# R9A09G057H register map
Vendor: Renesas Electronics; File version: 1.00
CPU: other r0p3, little endian, MPU, FPU, vendor SysTick, 4 interrupt priority bits, 480 interrupts
Registers are 32-bit, read-write, no defined reset value unless marked. A register's access mark holds for its fields unless they carry their own. Offsets are from the block's base; [hi:lo] are bit positions; lines under a group give offsets from that group; {n}, {i} and the like mark numbered series; 'fields as' and 'values as' point back to an identical list.

## R_GBETH0 — IO define file for tzc.
Base 0x15C30000
Same registers: R_GBETH1 0x15C40000
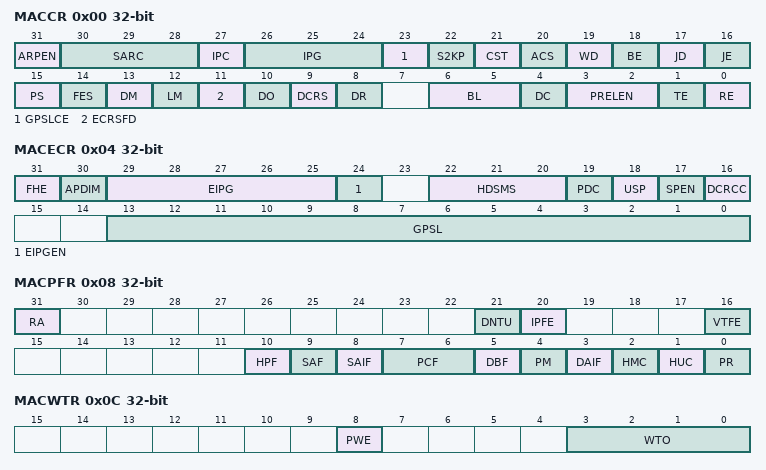
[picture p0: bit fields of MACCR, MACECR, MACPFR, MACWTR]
0x00 MACCR
  [31] ARPEN, [30:28] SARC, [27] IPC, [26:24] IPG, [23] GPSLCE, [22] S2KP, [21] CST, [20] ACS, [19] WD, [18] BE, [17] JD, [16] JE, [15] PS, [14] FES, [13] DM, [12] LM, [11] ECRSFD, [10] DO, [9] DCRS, [8] DR, [6:5] BL, [4] DC, [3:2] PRELEN, [1] TE, [0] RE
0x04 MACECR
  [31] FHE, [30] APDIM, [29:25] EIPG, [24] EIPGEN, [22:20] HDSMS, [19] PDC, [18] USP, [17] SPEN, [16] DCRCC, [13:0] GPSL
0x08 MACPFR
  [31] RA, [21] DNTU, [20] IPFE, [16] VTFE, [10] HPF, [9] SAF, [8] SAIF, [7:6] PCF, [5] DBF, [4] PM, [3] DAIF, [2] HMC, [1] HUC, [0] PR
0x0C MACWTR
  [8] PWE, [3:0] WTO
{0x10+4i} MACHTR{i} (i=0..7)
  [31:0] HT{32i+31}T{32i}
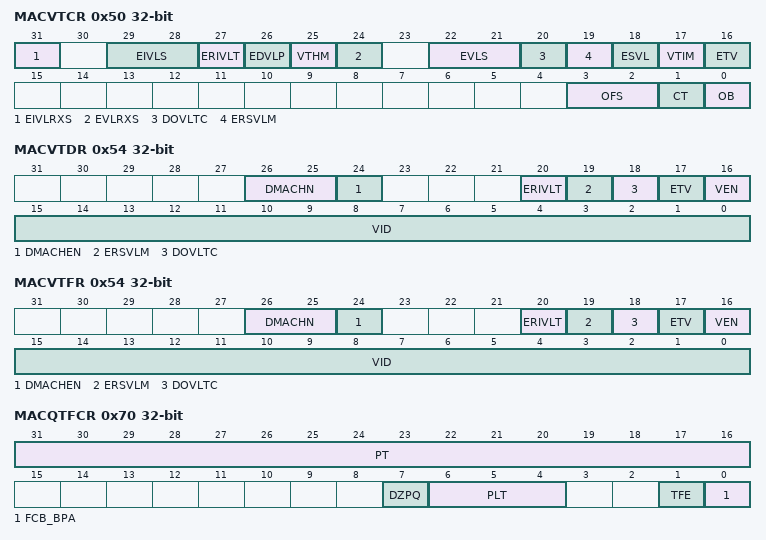
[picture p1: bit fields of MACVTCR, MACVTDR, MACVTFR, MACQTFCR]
0x50 MACVTCR
  [31] EIVLRXS, [29:28] EIVLS, [27] ERIVLT, [26] EDVLP, [25] VTHM, [24] EVLRXS, [22:21] EVLS, [20] DOVLTC, [19] ERSVLM, [18] ESVL, [17] VTIM, [16] ETV, [3:2] OFS, [1] CT, [0] OB
0x54 MACVTDR
  [26:25] DMACHN, [24] DMACHEN, [20] ERIVLT, [19] ERSVLM, [18] DOVLTC, [17] ETV, [16] VEN, [15:0] VID
0x54 MACVTFR
  fields as MACVTDR
0x58 MACVHTR
  [15:0] VLHT
0x70 MACQTFCR
  [31:16] PT, [7] DZPQ, [6:4] PLT, [1] TFE, [0] FCB_BPA
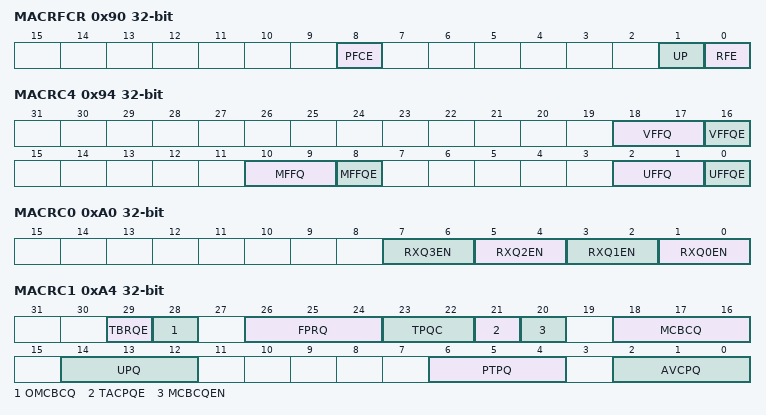
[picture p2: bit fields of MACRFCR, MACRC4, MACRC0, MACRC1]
0x90 MACRFCR
  [8] PFCE, [1] UP, [0] RFE
0x94 MACRC4
  [18:17] VFFQ, [16] VFFQE, [10:9] MFFQ, [8] MFFQE, [2:1] UFFQ, [0] UFFQE
0xA0 MACRC0
  [2n+1:2n] RXQ{n}EN (n=0..3)
0xA4 MACRC1
  [29] TBRQE, [28] OMCBCQ, [26:24] FPRQ, [23:22] TPQC, [21] TACPQE, [20] MCBCQEN, [18:16] MCBCQ, [14:12] UPQ, [6:4] PTPQ, [2:0] AVCPQ
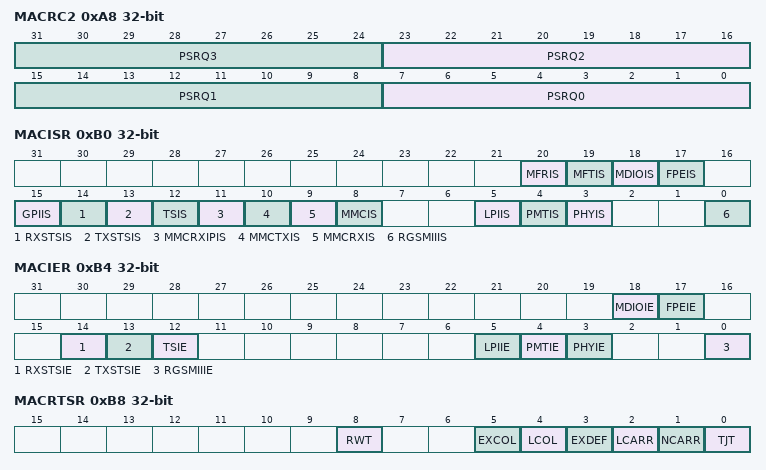
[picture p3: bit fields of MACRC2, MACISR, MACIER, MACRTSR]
0xA8 MACRC2
  [8n+7:8n] PSRQ{n} (n=0..3)
0xB0 MACISR ro
  [20] MFRIS, [19] MFTIS, [18] MDIOIS, [17] FPEIS, [15] GPIIS, [14] RXSTSIS, [13] TXSTSIS, [12] TSIS, [11] MMCRXIPIS, [10] MMCTXIS, [9] MMCRXIS, [8] MMCIS, [5] LPIIS, [4] PMTIS, [3] PHYIS, [0] RGSMIIIS
0xB4 MACIER
  [18] MDIOIE, [17] FPEIE, [14] RXSTSIE, [13] TXSTSIE, [12] TSIE, [5] LPIIE, [4] PMTIE, [3] PHYIE, [0] RGSMIIIE
0xB8 MACRTSR
  [8] RWT, [5] EXCOL, [4] LCOL, [3] EXDEF, [2] LCARR, [1] NCARR, [0] TJT
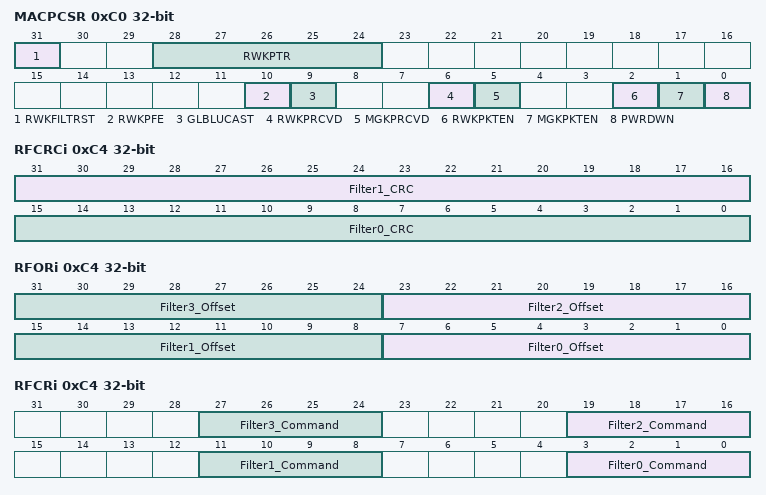
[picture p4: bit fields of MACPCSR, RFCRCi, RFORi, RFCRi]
0xC0 MACPCSR
  [31] RWKFILTRST, [28:24] RWKPTR ro, [10] RWKPFE, [9] GLBLUCAST, [6] RWKPRCVD, [5] MGKPRCVD, [2] RWKPKTEN, [1] MGKPKTEN, [0] PWRDWN
0xC4 RFBMRi
  [31:0] Filter0_Byte_Mask
0xC4 RFCRCi
  [31:16] Filter1_CRC, [15:0] Filter0_CRC
0xC4 RFORi
  [8n+7:8n] Filter{n}_Offset (n=0..3)
0xC4 RFCRi
  [8n+3:8n] Filter{n}_Command (n=0..3)
0xC4 MACRPFR
  [31:0] WKUPFRMFTR
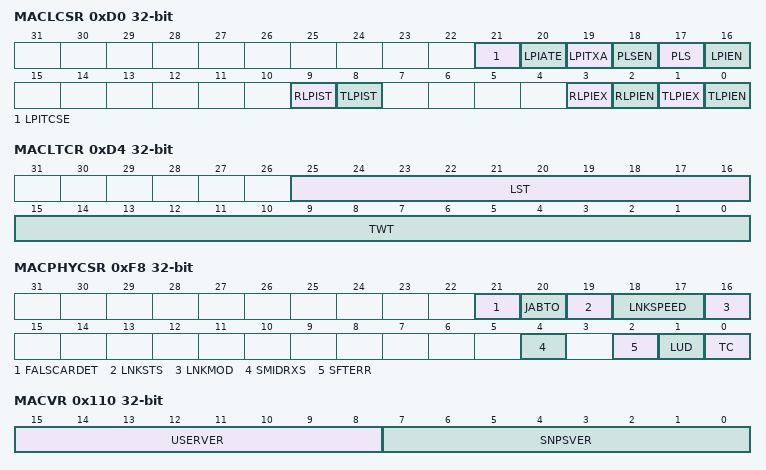
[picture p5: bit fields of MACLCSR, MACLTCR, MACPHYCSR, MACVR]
0xD0 MACLCSR
  [21] LPITCSE, [20] LPIATE, [19] LPITXA, [18] PLSEN, [17] PLS, [16] LPIEN, [9] RLPIST, [8] TLPIST, [3] RLPIEX, [2] RLPIEN, [1] TLPIEX, [0] TLPIEN
0xD4 MACLTCR
  [25:16] LST, [15:0] TWT
0xD8 MACLETR
  [19:3] LPIET
0xDC MAC1TCR
  [11:0] TIC_1US_CNTR
0xF8 MACPHYCSR
  [21] FALSCARDET ro, [20] JABTO ro, [19] LNKSTS ro, [18:17] LNKSPEED ro, [16] LNKMOD ro, [4] SMIDRXS, [2] SFTERR, [1] LUD, [0] TC
0x110 MACVR ro
  [15:8] USERVER, [7:0] SNPSVER
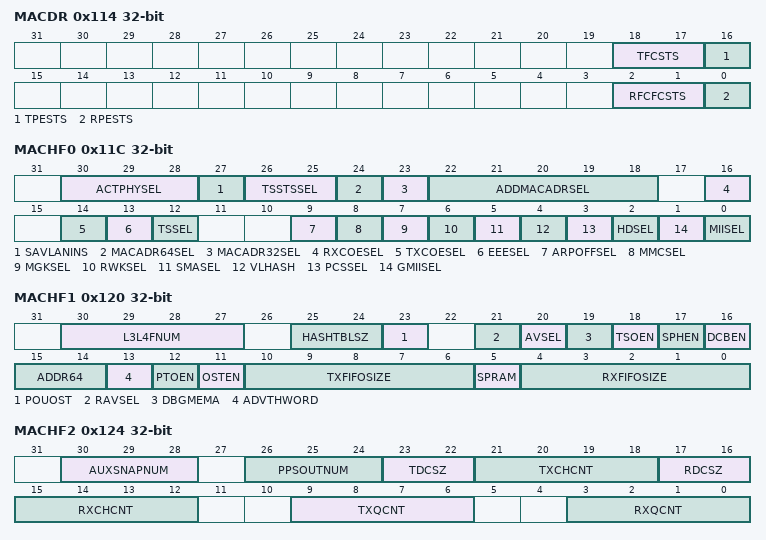
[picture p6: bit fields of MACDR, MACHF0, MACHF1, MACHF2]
0x114 MACDR ro
  [18:17] TFCSTS, [16] TPESTS, [2:1] RFCFCSTS, [0] RPESTS
0x11C MACHF0 ro
  [30:28] ACTPHYSEL, [27] SAVLANINS, [26:25] TSSTSSEL, [24] MACADR64SEL, [23] MACADR32SEL, [22:18] ADDMACADRSEL, [16] RXCOESEL, [14] TXCOESEL, [13] EEESEL, [12] TSSEL, [9] ARPOFFSEL, [8] MMCSEL, [7] MGKSEL, [6] RWKSEL, [5] SMASEL, [4] VLHASH, [3] PCSSEL, [2] HDSEL, [1] GMIISEL, [0] MIISEL
0x120 MACHF1 ro
  [30:27] L3L4FNUM, [25:24] HASHTBLSZ, [23] POUOST, [21] RAVSEL, [20] AVSEL, [19] DBGMEMA, [18] TSOEN, [17] SPHEN, [16] DCBEN, [15:14] ADDR64, [13] ADVTHWORD, [12] PTOEN, [11] OSTEN, [10:6] TXFIFOSIZE, [5] SPRAM, [4:0] RXFIFOSIZE
0x124 MACHF2 ro
  [30:28] AUXSNAPNUM, [26:24] PPSOUTNUM, [23:22] TDCSZ, [21:18] TXCHCNT, [17:16] RDCSZ, [15:12] RXCHCNT, [9:6] TXQCNT, [3:0] RXQCNT
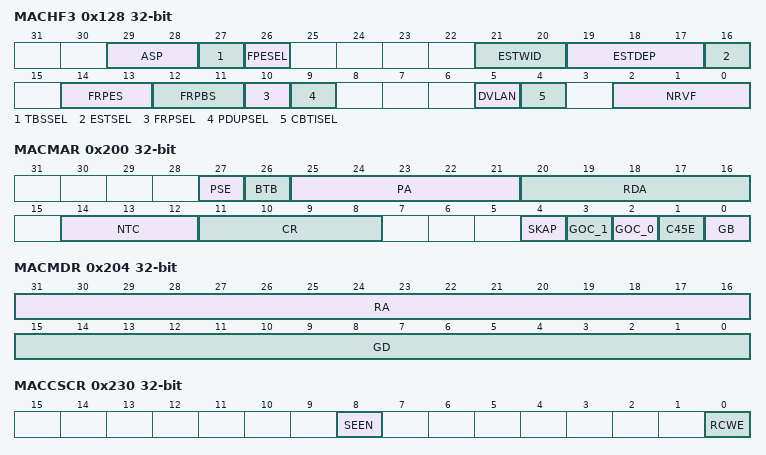
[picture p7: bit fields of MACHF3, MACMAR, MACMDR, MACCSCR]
0x128 MACHF3 ro
  [29:28] ASP, [27] TBSSEL, [26] FPESEL, [21:20] ESTWID, [19:17] ESTDEP, [16] ESTSEL, [14:13] FRPES, [12:11] FRPBS, [10] FRPSEL, [9] PDUPSEL, [5] DVLAN, [4] CBTISEL, [2:0] NRVF
0x200 MACMAR
  [27] PSE, [26] BTB, [25:21] PA, [20:16] RDA, [14:12] NTC, [11:8] CR, [4] SKAP, [3] GOC_1, [2] GOC_0, [1] C45E, [0] GB
0x204 MACMDR
  [31:16] RA, [15:0] GD
0x210 MACAAR
  [31:0] ARPPA
0x230 MACCSCR
  [8] SEEN, [0] RCWE
0x240 MACPTNR ro
  [31:0] MPTN
0x244 MACPTUR
  [31:0] MPTU
{0x300+8i} MAC_ADDRESS[{i}] (i=0..31) group — MAC_ADDRESS register group
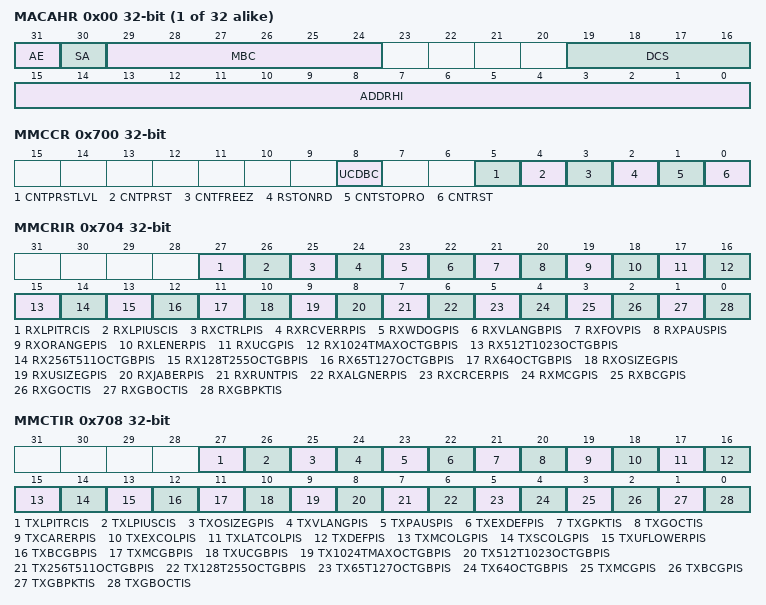
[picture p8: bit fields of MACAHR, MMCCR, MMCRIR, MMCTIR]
  0x00 MACAHR
    [31] AE, [30] SA, [29:24] MBC, [19:16] DCS, [15:0] ADDRHI
  0x04 MACALR
    [31:0] ADDRLO
0x700 MMCCR
  [8] UCDBC, [5] CNTPRSTLVL, [4] CNTPRST, [3] CNTFREEZ, [2] RSTONRD, [1] CNTSTOPRO, [0] CNTRST
0x704 MMCRIR ro
  [27] RXLPITRCIS, [26] RXLPIUSCIS, [25] RXCTRLPIS, [24] RXRCVERRPIS, [23] RXWDOGPIS, [22] RXVLANGBPIS, [21] RXFOVPIS, [20] RXPAUSPIS, [19] RXORANGEPIS, [18] RXLENERPIS, [17] RXUCGPIS, [16] RX1024TMAXOCTGBPIS, [15] RX512T1023OCTGBPIS, [14] RX256T511OCTGBPIS, [13] RX128T255OCTGBPIS, [12] RX65T127OCTGBPIS, [11] RX64OCTGBPIS, [10] RXOSIZEGPIS, [9] RXUSIZEGPIS, [8] RXJABERPIS, [7] RXRUNTPIS, [6] RXALGNERPIS, [5] RXCRCERPIS, [4] RXMCGPIS, [3] RXBCGPIS, [2] RXGOCTIS, [1] RXGBOCTIS, [0] RXGBPKTIS
0x708 MMCTIR ro
  [27] TXLPITRCIS, [26] TXLPIUSCIS, [25] TXOSIZEGPIS, [24] TXVLANGPIS, [23] TXPAUSPIS, [22] TXEXDEFPIS, [21] TXGPKTIS, [20] TXGOCTIS, [19] TXCARERPIS, [18] TXEXCOLPIS, [17] TXLATCOLPIS, [16] TXDEFPIS, [15] TXMCOLGPIS, [14] TXSCOLGPIS, [13] TXUFLOWERPIS, [12] TXBCGBPIS, [11] TXMCGBPIS, [10] TXUCGBPIS, [9] TX1024TMAXOCTGBPIS, [8] TX512T1023OCTGBPIS, [7] TX256T511OCTGBPIS, [6] TX128T255OCTGBPIS, [5] TX65T127OCTGBPIS, [4] TX64OCTGBPIS, [3] TXMCGPIS, [2] TXBCGPIS, [1] TXGBPKTIS, [0] TXGBOCTIS
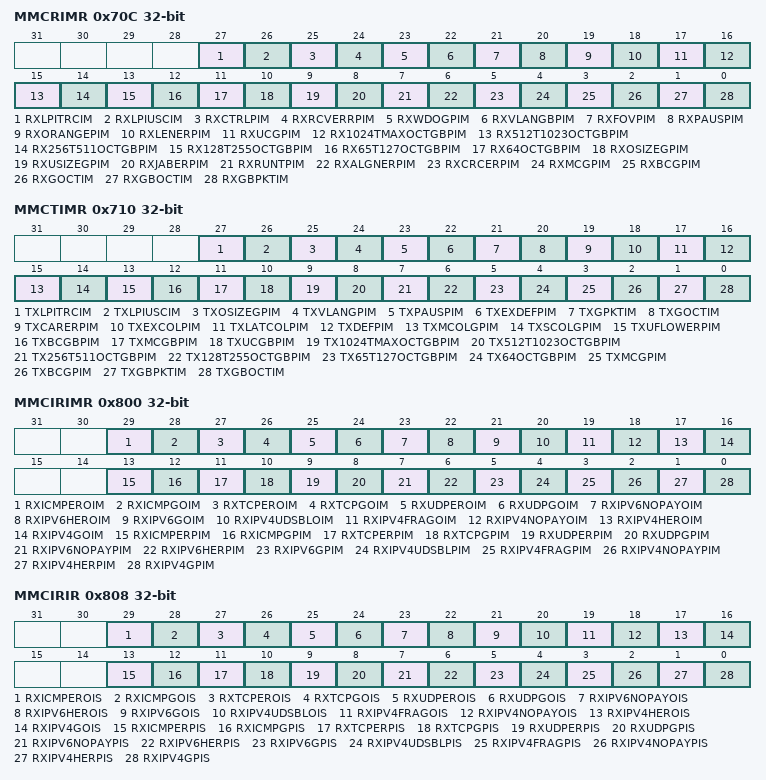
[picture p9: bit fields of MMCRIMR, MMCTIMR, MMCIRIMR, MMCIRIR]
0x70C MMCRIMR
  [27] RXLPITRCIM, [26] RXLPIUSCIM, [25] RXCTRLPIM, [24] RXRCVERRPIM, [23] RXWDOGPIM, [22] RXVLANGBPIM, [21] RXFOVPIM, [20] RXPAUSPIM, [19] RXORANGEPIM, [18] RXLENERPIM, [17] RXUCGPIM, [16] RX1024TMAXOCTGBPIM, [15] RX512T1023OCTGBPIM, [14] RX256T511OCTGBPIM, [13] RX128T255OCTGBPIM, [12] RX65T127OCTGBPIM, [11] RX64OCTGBPIM, [10] RXOSIZEGPIM, [9] RXUSIZEGPIM, [8] RXJABERPIM, [7] RXRUNTPIM, [6] RXALGNERPIM, [5] RXCRCERPIM, [4] RXMCGPIM, [3] RXBCGPIM, [2] RXGOCTIM, [1] RXGBOCTIM, [0] RXGBPKTIM
0x710 MMCTIMR
  [27] TXLPITRCIM, [26] TXLPIUSCIM, [25] TXOSIZEGPIM, [24] TXVLANGPIM, [23] TXPAUSPIM, [22] TXEXDEFPIM, [21] TXGPKTIM, [20] TXGOCTIM, [19] TXCARERPIM, [18] TXEXCOLPIM, [17] TXLATCOLPIM, [16] TXDEFPIM, [15] TXMCOLGPIM, [14] TXSCOLGPIM, [13] TXUFLOWERPIM, [12] TXBCGBPIM, [11] TXMCGBPIM, [10] TXUCGBPIM, [9] TX1024TMAXOCTGBPIM, [8] TX512T1023OCTGBPIM, [7] TX256T511OCTGBPIM, [6] TX128T255OCTGBPIM, [5] TX65T127OCTGBPIM, [4] TX64OCTGBPIM, [3] TXMCGPIM, [2] TXBCGPIM, [1] TXGBPKTIM, [0] TXGBOCTIM
0x714 TOCGBR ro
  [31:0] TXOCTGB
0x718 TPCGBR ro
  [31:0] TXPKTGB
0x71C TBPGR ro
  [31:0] TXBCASTG
0x720 TMPGR ro
  [31:0] TXMCASTG
0x724 T64PGBR ro
  [31:0] TX64OCTGB
0x728 T65PGBR ro
  [31:0] TX65_127OCTGB
0x72C T128PGBR ro
  [31:0] TX128_255OCTGB
0x730 T256PGBR ro
  [31:0] TX256_511OCTGB
0x734 T512PGBR ro
  [31:0] TX512_1023OCTGB
0x738 T1024PGBR ro
  [31:0] TX1024_MAXOCTGB
0x73C TUPGBR ro
  [31:0] TXUCASTGB
0x740 TMPGBR ro
  [31:0] TXMCASTGB
0x744 TBPGBR ro
  [31:0] TXBCASTGB
0x748 TUEPR ro
  [31:0] TXUNDRFLW
0x74C TSCGPR ro
  [31:0] TXSNGLCOLG
0x750 TMCGPR ro
  [31:0] TXMULTCOLG
0x754 TDPR ro
  [31:0] TXDEFRD
0x758 TLCPR ro
  [31:0] TXLATECOL
0x75C TECPR ro
  [31:0] TXEXSCOL
0x760 TCEPR ro
  [31:0] TXCARR
0x764 TOCGR ro
  [31:0] TXOCTG
0x768 TPCGR ro
  [31:0] TXPKTG
0x76C TEDER ro
  [31:0] TXEXSDEF
0x770 TPPR ro
  [31:0] TXPAUSE
0x774 TVPGR ro
  [31:0] TXVLANG
0x778 TOPGR ro
  [31:0] TXOSIZG
0x780 RPCGBR ro
  [31:0] RXPKTGB
0x784 ROCGBR ro
  [31:0] RXOCTGB
0x788 ROCGR ro
  [31:0] RXOCTG
0x78C RBPGR ro
  [31:0] RXBCASTG
0x790 RMPGR ro
  [31:0] RXMCASTG
0x794 RCEPR ro
  [31:0] RXCRCERR
0x798 RAEPR ro
  [31:0] RXALGNERR
0x79C RERRP ro
  [31:0] RXRUNTERR
0x7A0 RJEPR ro
  [31:0] RXJABERR
0x7A4 RUSPGD ro
  [31:0] RXUNDERSZG
0x7A8 ROPGR ro
  [31:0] RXOVERSZG
0x7AC R64PGBR ro
  [31:0] RX64OCTGB
0x7B0 R65PGBR ro
  [31:0] RX65_127OCTGB
0x7B4 R128PGBR ro
  [31:0] RX128_255OCTGB
0x7B8 R256PGBR ro
  [31:0] RX256_511OCTGB
0x7BC R512PGBR ro
  [31:0] RX512_1023OCTGB
0x7C0 R1024PGBR ro
  [31:0] RX1024_MAXOCTGB
0x7C4 RUCPGD ro
  [31:0] RXUCASTG
0x7C8 RLEPR ro
  [31:0] RXLENERR
0x7CC ROORTP ro
  [31:0] RXOUTOFRNG
0x7D0 RPPR ro
  [31:0] RXPAUSEPKT
0x7D4 RFOPR ro
  [31:0] RXFIFOOVFL
0x7D8 RVPGBR ro
  [31:0] RXVLANPKTGB
0x7DC RWEPR ro
  [31:0] RXWDGERR
0x7E0 RREPR ro
  [31:0] RXRCVERR
0x7E4 RCPGR ro
  [31:0] RXCTRLG
0x7EC TLUCR ro
  [31:0] TXLPIUSC
0x7F0 TLTCR ro
  [31:0] TXLPITRC
0x7F4 RLUCR ro
  [31:0] RXLPIUSC
0x7F8 RLTCR ro
  [31:0] RXLPITRC
0x800 MMCIRIMR
  [29] RXICMPEROIM, [28] RXICMPGOIM, [27] RXTCPEROIM, [26] RXTCPGOIM, [25] RXUDPEROIM, [24] RXUDPGOIM, [23] RXIPV6NOPAYOIM, [22] RXIPV6HEROIM, [21] RXIPV6GOIM, [20] RXIPV4UDSBLOIM, [19] RXIPV4FRAGOIM, [18] RXIPV4NOPAYOIM, [17] RXIPV4HEROIM, [16] RXIPV4GOIM, [13] RXICMPERPIM, [12] RXICMPGPIM, [11] RXTCPERPIM, [10] RXTCPGPIM, [9] RXUDPERPIM, [8] RXUDPGPIM, [7] RXIPV6NOPAYPIM, [6] RXIPV6HERPIM, [5] RXIPV6GPIM, [4] RXIPV4UDSBLPIM, [3] RXIPV4FRAGPIM, [2] RXIPV4NOPAYPIM, [1] RXIPV4HERPIM, [0] RXIPV4GPIM
0x808 MMCIRIR ro
  [29] RXICMPEROIS, [28] RXICMPGOIS, [27] RXTCPEROIS, [26] RXTCPGOIS, [25] RXUDPEROIS, [24] RXUDPGOIS, [23] RXIPV6NOPAYOIS, [22] RXIPV6HEROIS, [21] RXIPV6GOIS, [20] RXIPV4UDSBLOIS, [19] RXIPV4FRAGOIS, [18] RXIPV4NOPAYOIS, [17] RXIPV4HEROIS, [16] RXIPV4GOIS, [13] RXICMPERPIS, [12] RXICMPGPIS, [11] RXTCPERPIS, [10] RXTCPGPIS, [9] RXUDPERPIS, [8] RXUDPGPIS, [7] RXIPV6NOPAYPIS, [6] RXIPV6HERPIS, [5] RXIPV6GPIS, [4] RXIPV4UDSBLPIS, [3] RXIPV4FRAGPIS, [2] RXIPV4NOPAYPIS, [1] RXIPV4HERPIS, [0] RXIPV4GPIS
0x810 RV4GPR ro
  [31:0] RXIPV4GDPKT
0x814 RV4HEPR ro
  [31:0] RXIPV4HDRERRPKT
0x818 RV4NPPR ro
  [31:0] RXIPV4NOPAYPKT
0x81C RV4FPR ro
  [31:0] RXIPV4FRAGPKT
0x820 RV4UCDPR ro
  [31:0] RXIPV4UDSBLPKT
0x824 RV6GPR ro
  [31:0] RXIPV6GDPKT
0x828 RV6HEPR ro
  [31:0] RXIPV6HDRERRPKT
0x82C RV6NPPR ro
  [31:0] RXIPV6NOPAYPKT
0x830 RUDPGPR ro
  [31:0] RXUDPGDPKT
0x834 RUDPEPR ro
  [31:0] RXUDPERRPKT
0x838 RTCPGPR ro
  [31:0] RXTCPGDPKT
0x83C RTCPEPR ro
  [31:0] RXTCPERRPKT
0x840 RICMPGPR ro
  [31:0] RXICMPGDPKT
0x844 RICMPEPR ro
  [31:0] RXICMPERRPKT
0x850 RV4GOR ro
  [31:0] RXIPV4GDOCT
0x854 RV4HEOR ro
  [31:0] RXIPV4HDRERROCT
0x858 RV4NPOR ro
  [31:0] RXIPV4NOPAYOCT
0x85C RV4FOR ro
  [31:0] RXIPV4FRAGOCT
0x860 RV4UCDOR ro
  [31:0] RXIPV4UDSBLOCT
0x864 RV6GOR ro
  [31:0] RXIPV6GDOCT
0x868 RV6HEOR ro
  [31:0] RXIPV6HDRERROCT
0x86C RV6NPOR ro
  [31:0] RXIPV6NOPAYOCT
0x870 RUDPGOR ro
  [31:0] RXUDPGDOCT
0x874 RUDPEOR ro
  [31:0] RXUDPERROCT
0x878 RTCPGOR ro
  [31:0] RXTCPGDOCT
0x87C RTCPEOR ro
  [31:0] RXTCPERROCT
0x880 RICMPGOR ro
  [31:0] RXICMPGDOCT
0x884 RICMPEOR ro
  [31:0] RXICMPERROCT
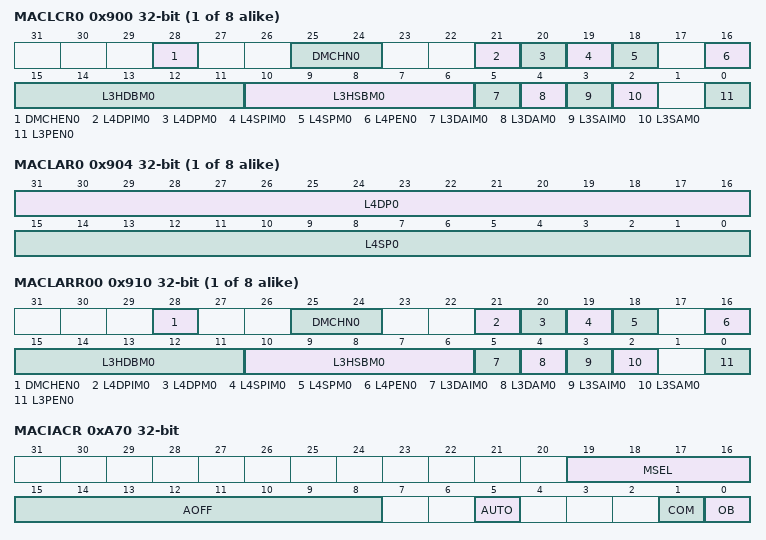
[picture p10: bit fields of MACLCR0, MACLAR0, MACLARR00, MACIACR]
{0x900+0x30*i} MACLCR{i} (i=0..7)
  [28] DMCHEN0, [25:24] DMCHN0, [21] L4DPIM0, [20] L4DPM0, [19] L4SPIM0, [18] L4SPM0, [16] L4PEN0, [15:11] L3HDBM0, [10:6] L3HSBM0, [5] L3DAIM0, [4] L3DAM0, [3] L3SAIM0, [2] L3SAM0, [0] L3PEN0
{0x904+0x30*i} MACLAR{i} (i=0..7)
  [31:16] L4DP0, [15:0] L4SP0
{0x910+0x30*i} MACLARR{i:02} (i=0..7)
  fields as MACLCR0
{0x734+0x30*i} MACLARR{i} (i=10..17)
  [31:0] L3A10
{0x558+0x30*i} MACLARR{i} (i=20..27)
  [31:0] L3A20
{0x37C+0x30*i} MACLARR{i} (i=30..37)
  [31:0] L3A30
0xA70 MACIACR
  [19:16] MSEL, [15:8] AOFF, [5] AUTO, [1] COM, [0] OB
0xA74 MACIADR
  [31:0] DATA
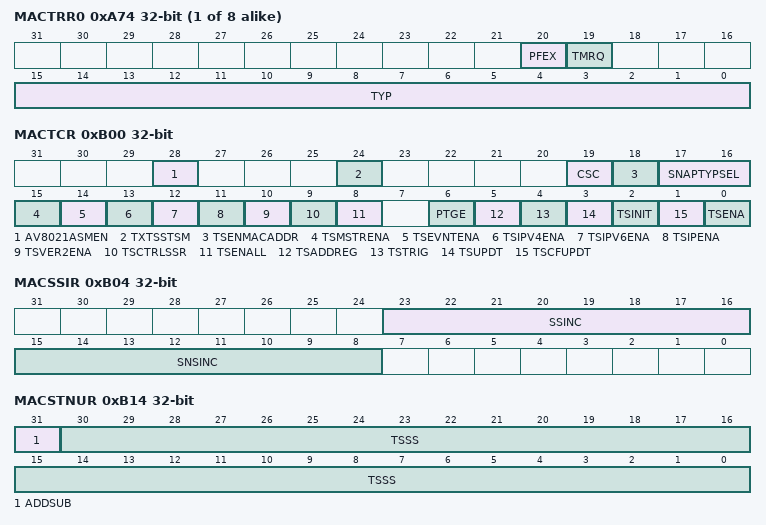
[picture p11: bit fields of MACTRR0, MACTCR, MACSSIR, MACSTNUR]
{0xA74+4i} MACTRR{i} (i=0..7)
  [20] PFEX, [19] TMRQ, [15:0] TYP
0xB00 MACTCR
  [28] AV8021ASMEN, [24] TXTSSTSM, [19] CSC, [18] TSENMACADDR, [17:16] SNAPTYPSEL, [15] TSMSTRENA, [14] TSEVNTENA, [13] TSIPV4ENA, [12] TSIPV6ENA, [11] TSIPENA, [10] TSVER2ENA, [9] TSCTRLSSR, [8] TSENALL, [6] PTGE, [5] TSADDREG, [4] TSTRIG, [3] TSUPDT, [2] TSINIT, [1] TSCFUPDT, [0] TSENA
0xB04 MACSSIR
  [23:16] SSINC, [15:8] SNSINC
0xB08 MACSTSR ro
  [31:0] TSS
0xB0C MACSTNR ro
  [30:0] TSSS
0xB10 MACSTSUR
  [31:0] TSS
0xB14 MACSTNUR
  [31] ADDSUB, [30:0] TSSS
0xB18 MACTAR
  [31:0] TSAR
0xB1C MACSTHWS
  [15:0] TSHWR
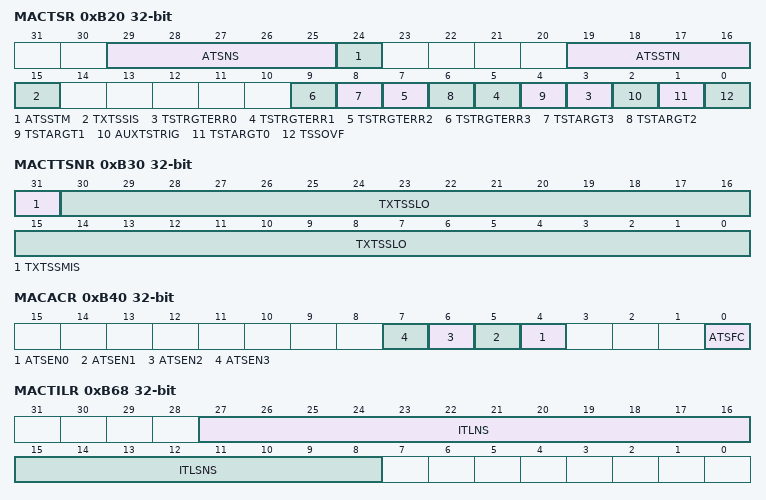
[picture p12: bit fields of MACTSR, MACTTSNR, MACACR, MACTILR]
0xB20 MACTSR ro
  [29:25] ATSNS, [24] ATSSTM, [19:16] ATSSTN, [15] TXTSSIS, [2n+3] TSTRGTERR{n} (n=0..3), [8] TSTARGT3, [6] TSTARGT2, [4] TSTARGT1, [2] AUXTSTRIG, [1] TSTARGT0, [0] TSSOVF
0xB30 MACTTSNR ro
  [31] TXTSSMIS, [30:0] TXTSSLO
0xB34 MACTTSSR ro
  [31:0] TXTSSHI
0xB40 MACACR
  [n+4] ATSEN{n} (n=0..3), [0] ATSFC
0xB48 MACATNR ro
  [31:0] AUXTSLO
0xB4C MACATSR ro
  [31:0] AUXTSHI
0xB50 MACTIACR
  [31:0] OSTIAC
0xB54 MACTEACR
  [31:0] OSTEAC
0xB58 MACTICNR
  [31:0] TSIC
0xB5C MACTECNR
  [31:0] TSEC
0xB60 MACTICSR
  [15:8] TSICSNS
0xB64 MACTECSR
  [15:8] TSECSNS
0xB68 MACTILR ro
  [27:16] ITLNS, [15:8] ITLSNS
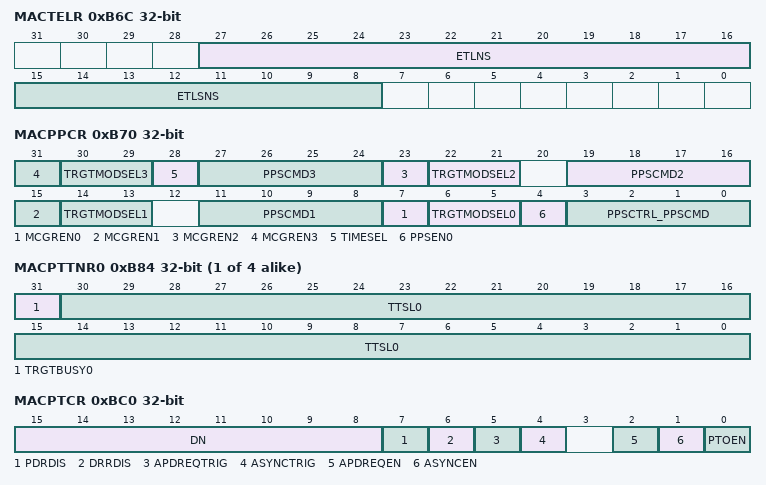
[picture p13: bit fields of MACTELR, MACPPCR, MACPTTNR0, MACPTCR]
0xB6C MACTELR ro
  [27:16] ETLNS, [15:8] ETLSNS
0xB70 MACPPCR
  [8n+7] MCGREN{n} (n=0..3), [8n+6:8n+5] TRGTMODSEL{n} (n=0..3), [28] TIMESEL, [27:24] PPSCMD3, [19:16] PPSCMD2, [11:8] PPSCMD1, [4] PPSEN0, [3:0] PPSCTRL_PPSCMD
{0xB80+0x10*i} MACPTTSR{i} (i=0..3)
  [31:0] TSTRH0
{0xB84+0x10*i} MACPTTNR{i} (i=0..3)
  [31] TRGTBUSY0, [30:0] TTSL0
{0xB88+0x10*i} MACPIR{i} (i=0..3)
  [31:0] PPSINT0
{0xB8C+0x10*i} MACPWR{i} (i=0..3)
  [31:0] PPSWIDTH0
0xBC0 MACPTCR
  [15:8] DN, [7] PDRDIS, [6] DRRDIS, [5] APDREQTRIG, [4] ASYNCTRIG, [2] APDREQEN, [1] ASYNCEN, [0] PTOEN
0xBC4 MACSPI0
  [31:0] SPI0
0xBC8 MACSPI1
  [31:0] SPI1
0xBCC MACSPI2
  [15:0] SPI2
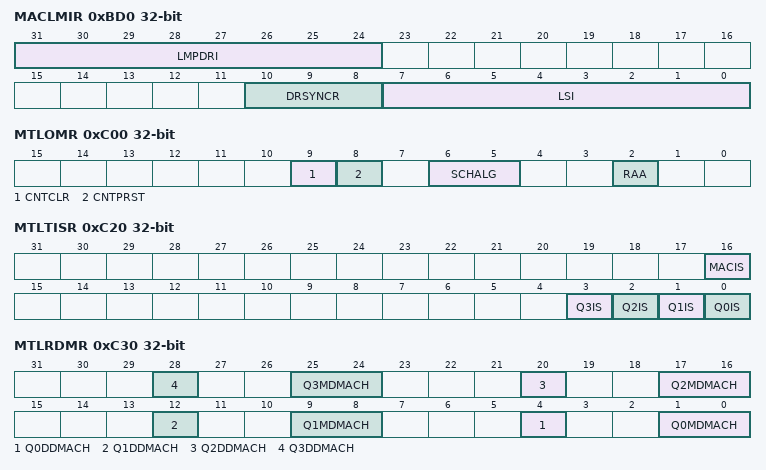
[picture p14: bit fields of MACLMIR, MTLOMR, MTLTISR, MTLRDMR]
0xBD0 MACLMIR
  [31:24] LMPDRI, [10:8] DRSYNCR, [7:0] LSI
0xC00 MTLOMR
  [9] CNTCLR, [8] CNTPRST, [6:5] SCHALG, [2] RAA
0xC20 MTLTISR ro
  [16] MACIS, [n] Q{n}IS (n=0..3)
0xC30 MTLRDMR
  [8n+4] Q{n}DDMACH (n=0..3), [8n+1:8n] Q{n}MDMACH (n=0..3)
{0xD00+0x40*i} MTL_Q[{i}] (i=0..3) group — MTL_Q register group
  0x00 MTLTOMR
    [20:16] TQS, [6:4] TTC, [3:2] TXQEN, [1] TSF, [0] FTQ
  0x04 MTLTUR ro
    [11] UFCNTOVF, [10:0] UFFRMCNT
  0x08 MTLTDR ro
    [22:20] STXSTSF, [18:16] PTXQ, [5] TXSTSFSTS, [4] TXQSTS, [3] TWCSTS, [2] TRCSTS, [1:0] TXQPAUSED
  0x10 MTLTECR
    [6:4] SLC, [3] CC, [2] AVALG
  0x14 MTLTESR ro
    [23:0] ABS
  0x18 MTLTQWR
    [20:0] ISCQW
  0x1C MTLTSR
    [13:0] SSC
  0x20 MTLTHR
    [28:0] HC
  0x24 MTLTLR
    [28:0] LC
  0x2C MTLQICSR
    [24] RXOIE, [16] RXOVFIS, [9] ABPSIE, [8] TXUIE, [1] ABPSIS, [0] TXUNFIS
  0x30 MTLROMR
    [24:20] RQS, [17:14] RFD, [11:8] RFA, [7] EHFC, [6] DIS_TCP_EF, [5] RSF, [4] FEP, [3] FUP, [1:0] RTC
  0x34 MTLRMPOC ro
    [27] MISCNTOVF, [26:16] MISPKTCNT, [11] OVFCNTOVF, [10:0] OVFPKTCNT
  0x38 MTLRDR ro
    [29:16] PRXQ, [5:4] RXQSTS, [2:1] RRCSTS, [0] RWCSTS
  0x3C MTLRCR
    [2:0] RXQ_WEGT
0x1000 DMR
  [17:16] INTM, [14:12] PR, [11] TXPR, [9] ARBC, [8] DSPW, [4:2] TAA, [1] DA, [0] SWR
0x1004 DSMR
  [31] EN_LPI, [30] LPI_XIT_PKT, [27:24] WR_OSR_LMT, [19:16] RD_OSR_LMT, [13] ONEKBBE, [12] AAL, [10] AALE, [3] BLEN16, [2] BLEN8, [1] BLEN4, [0] FB
0x1008 DISR ro
  [17] MACIS, [16] MTLIS, [n] DC{n}IS (n=0..3)
0x100C DDS0 ro
  [31:28] TPS2, [27:24] RPS2, [23:20] TPS1, [19:16] RPS1, [15:12] TPS0, [11:8] RPS0, [1] AXRHSTS, [0] AXWHSTS
0x1010 DDS1 ro
  [7:4] TPS3, [3:0] RPS3
0x1040 ALEIR
  [3:0] LPIEI
{0x1100+0x80*i} DMA_CH[{i}] (i=0..3) group — DMA_CH register group
  0x00 DCCR
    [20:18] DSL, [16] PBLx8
  0x04 DCTCR
    [27:24] TQOS, [21:16] TxPBL, [15] IPBL, [4] OSF, [3:1] TCW, [0] ST
  0x08 DCRCR
    [31] RPF, [21:16] RxPBL, [14:5] RBSZ_13_5, [4:1] RBSZ_4_0, [0] SR
  0x14 DCTLAR
    [31:4] TDESLA
  0x1C DCRLAR
    [31:4] RDESLA
  0x20 DCTTPR
    [31:4] TDTP
  0x28 DCRTPR
    [31:4] RDTP
  0x2C DCTRLR
    [9:0] TDRL
  0x30 DCRC2R
    [24:18] ARBS, [9:0] RDRL
  0x34 DCIER
    [15] NIE, [14] AIE, [13] CDEE, [12] FBEE, [11] ERIE, [10] ETIE, [9] RWTE, [8] RSE, [7] RBUE, [6] RIE, [2] TBUE, [1] TXSE, [0] TIE
  0x38 DCRIWT
    [17:16] RWTU, [7:0] RWT
  0x3C DCSFCS
    [19:16] RSN ro, [15:4] SIV, [1] ASC, [0] ESC
  0x44 DCCATDR ro
    [31:0] CURTDESAPTR
  0x4C DCCARDR ro
    [31:0] CURRDESAPTR
  0x54 DCCATBR ro
    [31:0] CURTBUFAPTR
  0x5C DCCARBR ro
    [31:0] CURRBUFAPTR
  0x60 DCSR
    [21:19] REB ro, [18:16] TEB ro, [15] NIS, [14] AIS, [13] CDE, [12] FBE, [11] ERI, [10] ETI, [9] RWT, [8] RPS, [7] RBU, [6] RI, [2] TBU, [1] TPS, [0] TI
  0x64 DCMFCR ro
    [15] MFCO, [10:0] MFC
